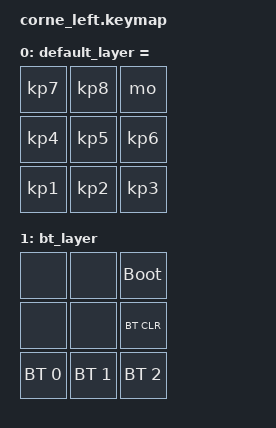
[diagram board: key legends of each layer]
#include <behaviors.dtsi>
#include <dt-bindings/zmk/keys.h>
#include <dt-bindings/zmk/bt.h>

/ {
	keymap {
		compatible = "zmk,keymap";
		
		default_layer = {
			bindings = <
				&kp KP_N7	&kp KP_N8	mo 1
				&kp KP_N4	&kp KP_N5	&kp KP_N6 
				&kp KP_N1	&kp KP_N2	&kp KP_N3
			>;
		};

		bt_layer {
			bindings = <
				&none	&none	&bootloader
				&none	&none	&bt BT_CLR
				&bt BT_SEL0	&bt BT_SEL1	&bt BT_SEL 2
			>;
		};
	};
};
